# ATSAMRH71F20C device description
Architecture: CORTEX-M7; Family: SAMRH; Series: SAMRH71
Registers are 32-bit, read-write, no defined reset value unless marked. A register's access mark holds for its fields unless they carry their own. Offsets are from the block's base; [hi:lo] are bit positions; {n}, {i} and the like mark numbered series.

## GPNVMBITS (HEFC module)
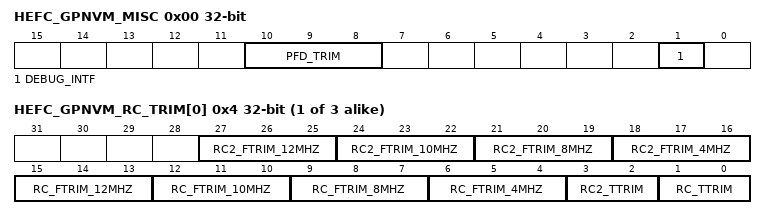
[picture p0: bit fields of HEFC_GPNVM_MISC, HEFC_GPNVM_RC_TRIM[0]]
0x00 HEFC_GPNVM_MISC — HEFC GPNVM word miscellaneous
  [10:8] PFD_TRIM — PFD Trim value
  [1] DEBUG_INTF — Debug interface Selection
    0=JTAG; 1=SWD
{0x4+4i} HEFC_GPNVM_RC_TRIM[{i}] (i=0..2) — HEFC GPNVM word RC trim (1..3)
  [27:25] RC2_FTRIM_12MHZ — RC2 Frequency Trim 12MHz
  [24:22] RC2_FTRIM_10MHZ — RC2 Frequency Trim 10MHz
  [21:19] RC2_FTRIM_8MHZ — RC2 Frequency Trim 8MHz
  [18:16] RC2_FTRIM_4MHZ — RC2 Frequency Trim 4MHz
  [15:13] RC_FTRIM_12MHZ — RC Frequency Trim 12MHz
  [12:10] RC_FTRIM_10MHZ — RC Frequency Trim 10MHz
  [9:7] RC_FTRIM_8MHZ — RC Frequency Trim 8MHz
  [6:4] RC_FTRIM_4MHZ — RC Frequency Trim 4MHz
  [3:2] RC2_TTRIM — RC2 Temperature Trim
  [1:0] RC_TTRIM — RC Temperature Trim

## HSMC — Harden Static Memory Controller
Instances: HSMC 0x40081000
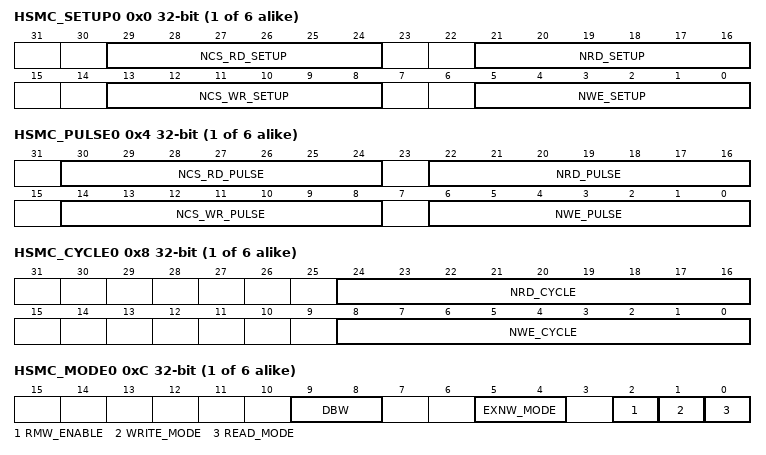
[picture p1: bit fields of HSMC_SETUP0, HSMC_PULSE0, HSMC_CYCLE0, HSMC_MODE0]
{0x0+0x10*i} HSMC_SETUP{i} (i=0..5) — HSMC Setup Register (CS_number = {i})
  [29:24] NCS_RD_SETUP — NCS Setup Length in READ Access
  [21:16] NRD_SETUP — NRD Setup Length
  [13:8] NCS_WR_SETUP — NCS Setup Length in WRITE Access
  [5:0] NWE_SETUP — NWE Setup Length
{0x4+0x10*i} HSMC_PULSE{i} (i=0..5) — HSMC Pulse Register (CS_number = {i})
  [30:24] NCS_RD_PULSE — NCS Pulse Length in READ Access
  [22:16] NRD_PULSE — NRD Pulse Length
  [14:8] NCS_WR_PULSE — NCS Pulse Length in WRITE Access
  [6:0] NWE_PULSE — NWE Pulse Length
{0x8+0x10*i} HSMC_CYCLE{i} (i=0..5) — HSMC Cycle Register (CS_number = {i})
  [24:16] NRD_CYCLE — Total Read Cycle Length
  [8:0] NWE_CYCLE — Total Write Cycle Length
{0xC+0x10*i} HSMC_MODE{i} (i=0..5) — HSMC Mode Register (CS_number = {i})
  [9:8] DBW — Data Bus Width
    0=_8_BIT (8-bit Data Bus); 1=_16_BIT (16-bit Data Bus); 2=_32_BIT (32-bit Data Bus)
  [5:4] EXNW_MODE — NWAIT Mode
    0=DISABLED (Disabled-The NWAIT input signal is ignored on the corresponding chip select.); 2=FROZEN (Frozen Mode-If asserted, the NWAIT signal freezes the current read or write cycle. After deassertion, the read/write cycle is resumed from the point where it was stopped.); 3=READY (Ready Mode-The NWAIT signal indicates the availability of the external device at the end of the pulse of the controlling read or write signal, to complete the access. If high, the access normally completes. If low, the access is extended until NWAIT returns high.)
  [2] RMW_ENABLE — Read-Modify Write enable
  [1] WRITE_MODE
  [0] READ_MODE
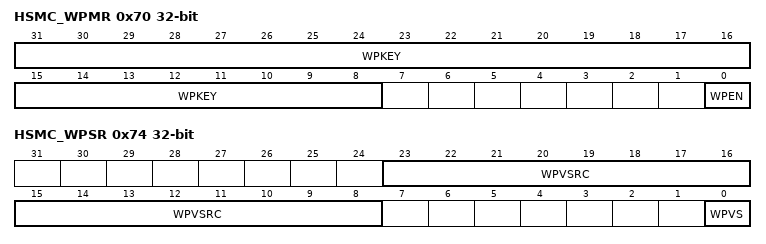
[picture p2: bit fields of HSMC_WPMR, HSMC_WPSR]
0x70 HSMC_WPMR — HSMC Write Protection Mode Register
  [31:8] WPKEY — Write Protection Key
    0x534D43=PASSWD (Writing any other value in this field aborts the write operation of the WPEN bit. Always reads as 0.)
  [0] WPEN — Write Protect Enable
0x74 HSMC_WPSR ro — HSMC Write Protection Status Register
  [23:8] WPVSRC — Write Protection Violation Source
  [0] WPVS — Write Protection Violation Status

## ICM_DESCRIPTOR — Region Descriptor Structure
0x00 RADDR — Region Start Address
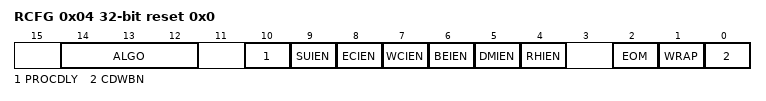
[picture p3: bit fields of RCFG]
0x04 RCFG reset 0x0 — Region Configuration
  [14:12] ALGO — SHA Algorithm
    0=SHA1 (SHA1 algorithm processed); 1=SHA256 (SHA256 algorithm processed); 4=SHA224 (SHA224 algorithm processed)
  [10] PROCDLY — SHA Processing Delay
    0=SHORT; 1=LONG
  [9] SUIEN — Region Status Updated Interrupt Enable
    0=EN; 1=DIS
  [8] ECIEN — Region End bit Condition detected Interrupt Enable
    0=EN; 1=DIS
  [7] WCIEN — Region Wrap Condition Detected Interrupt Enable
    0=EN; 1=DIS
  [6] BEIEN — Region Bus Error Interrupt Enable
    0=EN; 1=DIS
  [5] DMIEN — Region Digest Mismatch Interrupt Enable
    0=EN; 1=DIS
  [4] RHIEN — Region Hash Interrupt Enable
    0=EN; 1=DIS
  [2] EOM — End of Monitoring
    0=NO; 1=YES
  [1] WRAP — Region Wrap
    0=NO; 1=YES
  [0] CDWBN — Compare Digest Write Back
    0=WRBA; 1=COMP
0x08 RCTRL — Region Control
  [15:0] TRSIZE — Transfer Size for the Current Chunk of Data
0x0C RNEXT — Region Next Address
  [31:2] NEXT — Region Transfer Descriptor Next Address

## Notices in the file
Copyright (c) 2018 Microchip Technology Inc.
SPDX-License-Identifier: Apache-2.0
Licensed under the Apache License, Version 2.0 (the "License");
you may not use this file except in compliance with the License.
You may obtain a copy of the License at
http://www.apache.org/licenses/LICENSE-2.0
Unless required by applicable law or agreed to in writing, software
distributed under the License is distributed on an "AS IS" BASIS,
WITHOUT WARRANTIES OR CONDITIONS OF ANY KIND, either express or implied.
See the License for the specific language governing permissions and
limitations under the License.
